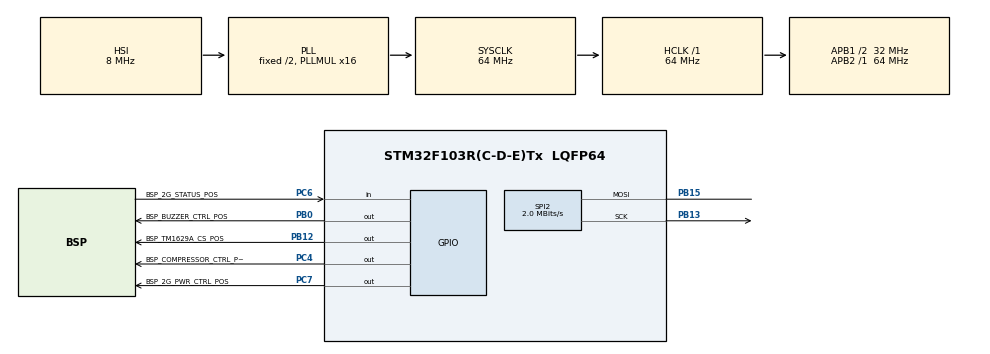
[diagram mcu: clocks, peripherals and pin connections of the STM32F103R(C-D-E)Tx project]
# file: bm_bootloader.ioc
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IWDG.Reload=4000
Mcu.Family=STM32F1
Mcu.Name=STM32F103R(C-D-E)Tx
Mcu.Package=LQFP64
NVIC.PriorityGroup=NVIC_PRIORITYGROUP_4
NVIC.SPI2_IRQn=true\:0\:0\:false\:false\:true\:true
PA13.Mode=JTAG_5_pins
PA13.Signal=SYS_JTMS-SWDIO
PA14.Mode=JTAG_5_pins
PA14.Signal=SYS_JTCK-SWCLK
PA15.Mode=JTAG_5_pins
PA15.Signal=SYS_JTDI
PB0.GPIO_Label=BSP_BUZZER_CTRL_POS
PB0.Signal=GPIO_Output
PB12.GPIO_Label=BSP_TM1629A_CS_POS
PB12.Signal=GPIO_Output
PB13.Mode=Simplex_Bidirectional_Master
PB13.Signal=SPI2_SCK
PB15.Mode=Simplex_Bidirectional_Master
PB15.Signal=SPI2_MOSI
PB3.Mode=JTAG_5_pins
PB3.Signal=SYS_JTDO-TRACESWO
PB4.Mode=JTAG_5_pins
PB4.Signal=SYS_NJTRST
PC4.GPIO_Label=BSP_COMPRESSOR_CTRL_POS
PC4.Signal=GPIO_Output
PC6.GPIO_Label=BSP_2G_STATUS_POS
PC6.GPIO_PuPd=GPIO_PULLDOWN
PC6.Signal=GPIO_Input
PC7.GPIO_Label=BSP_2G_PWR_CTRL_POS
PC7.Signal=GPIO_Output
ProjectManager.HeapSize=0x00
ProjectManager.StackSize=0x400
ProjectManager.TargetToolchain=EWARM V8
RCC.AHBFreq_Value=64000000
RCC.APB1CLKDivider=RCC_HCLK_DIV2
RCC.APB1Freq_Value=32000000
RCC.APB1TimFreq_Value=64000000
RCC.APB2Freq_Value=64000000
RCC.APB2TimFreq_Value=64000000
RCC.HCLKFreq_Value=64000000
RCC.PLLMUL=RCC_PLL_MUL16
RCC.SYSCLKFreq_VALUE=64000000
RCC.SYSCLKSource=RCC_SYSCLKSOURCE_PLLCLK
RCC.USBFreq_Value=64000000
SPI2.BaudRatePrescaler=SPI_BAUDRATEPRESCALER_16
SPI2.CalculateBaudRate=2.0 MBits/s
SPI2.Direction=SPI_DIRECTION_1LINE
SPI2.FirstBit=SPI_FIRSTBIT_LSB
SPI2.Mode=SPI_MODE_MASTER
SPI2.VirtualType=VM_MASTER
VP_IWDG_VS_IWDG.Mode=IWDG_Activate
board=custom

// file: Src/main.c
/**
  ******************************************************************************
  * @file           : main.c
  * @brief          : Main program body
  ******************************************************************************
  ** This notice applies to any and all portions of this file
  * that are not between comment pairs USER CODE BEGIN and
  * USER CODE END. Other portions of this file, whether
  * inserted by the user or by software development tools
  * are owned by their respective copyright owners.
  *
  * COPYRIGHT(c) 2019 STMicroelectronics
  *
  * Redistribution and use in source and binary forms, with or without modification,
  * are permitted provided that the following conditions are met:
  *   1. Redistributions of source code must retain the above copyright notice,
  *      this list of conditions and the following disclaimer.
  *   2. Redistributions in binary form must reproduce the above copyright notice,
  *      this list of conditions and the following disclaimer in the documentation
  *      and/or other materials provided with the distribution.
  *   3. Neither the name of STMicroelectronics nor the names of its contributors
  *      may be used to endorse or promote products derived from this software
  *      without specific prior written permission.
  *
  * THIS SOFTWARE IS PROVIDED BY THE COPYRIGHT HOLDERS AND CONTRIBUTORS "AS IS"
  * AND ANY EXPRESS OR IMPLIED WARRANTIES, INCLUDING, BUT NOT LIMITED TO, THE
  * IMPLIED WARRANTIES OF MERCHANTABILITY AND FITNESS FOR A PARTICULAR PURPOSE ARE
  * DISCLAIMED. IN NO EVENT SHALL THE COPYRIGHT HOLDER OR CONTRIBUTORS BE LIABLE
  * FOR ANY DIRECT, INDIRECT, INCIDENTAL, SPECIAL, EXEMPLARY, OR CONSEQUENTIAL
  * DAMAGES (INCLUDING, BUT NOT LIMITED TO, PROCUREMENT OF SUBSTITUTE GOODS OR
  * SERVICES; LOSS OF USE, DATA, OR PROFITS; OR BUSINESS INTERRUPTION) HOWEVER
  * CAUSED AND ON ANY THEORY OF LIABILITY, WHETHER IN CONTRACT, STRICT LIABILITY,
  * OR TORT (INCLUDING NEGLIGENCE OR OTHERWISE) ARISING IN ANY WAY OUT OF THE USE
  * OF THIS SOFTWARE, EVEN IF ADVISED OF THE POSSIBILITY OF SUCH DAMAGE.
  *
  ******************************************************************************
  */
#include "main.h"
#include "stm32f1xx_hal.h"
#include "iwdg.h"
#include "spi.h"
#include "gpio.h"

/* USER CODE BEGIN Includes */
#include "log.h"
#include "bootloader.h"
/* USER CODE END Includes */

/* USER CODE BEGIN PV */
/* Private variables ---------------------------------------------------------*/

/* USER CODE END PV */

void SystemClock_Config(void);

/* USER CODE BEGIN PFP */
/* Private function prototypes -----------------------------------------------*/

/* USER CODE END PFP */

int main(void)
{

  /* MCU Configuration----------------------------------------------------------*/

  /* Reset of all peripherals, Initializes the Flash interface and the Systick. */
  HAL_Init();

  /* Configure the system clock */
  SystemClock_Config();

  /* Initialize all configured peripherals */
  MX_GPIO_Init();
  MX_SPI2_Init();
  //MX_IWDG_Init();
  /* USER CODE BEGIN 2 */
  log_init();
  /* USER CODE END 2 */

  /* Infinite loop */
  while (1)
  {

  /* USER CODE BEGIN 3 */
  bootloader();
  }
  /* USER CODE END 3 */

}

void SystemClock_Config(void)
{

  RCC_OscInitTypeDef RCC_OscInitStruct;
  RCC_ClkInitTypeDef RCC_ClkInitStruct;

    /**Initializes the CPU, AHB and APB busses clocks
    */
  RCC_OscInitStruct.OscillatorType = RCC_OSCILLATORTYPE_HSI|RCC_OSCILLATORTYPE_LSI;
  RCC_OscInitStruct.HSIState = RCC_HSI_ON;
  RCC_OscInitStruct.HSICalibrationValue = 16;
  RCC_OscInitStruct.LSIState = RCC_LSI_ON;
  RCC_OscInitStruct.PLL.PLLState = RCC_PLL_ON;
  RCC_OscInitStruct.PLL.PLLSource = RCC_PLLSOURCE_HSI_DIV2;
  RCC_OscInitStruct.PLL.PLLMUL = RCC_PLL_MUL16;
  if (HAL_RCC_OscConfig(&RCC_OscInitStruct) != HAL_OK)
  {
    _Error_Handler(__FILE__, __LINE__);
  }

    /**Initializes the CPU, AHB and APB busses clocks
    */
  RCC_ClkInitStruct.ClockType = RCC_CLOCKTYPE_HCLK|RCC_CLOCKTYPE_SYSCLK
                              |RCC_CLOCKTYPE_PCLK1|RCC_CLOCKTYPE_PCLK2;
  RCC_ClkInitStruct.SYSCLKSource = RCC_SYSCLKSOURCE_PLLCLK;
  RCC_ClkInitStruct.AHBCLKDivider = RCC_SYSCLK_DIV1;
  RCC_ClkInitStruct.APB1CLKDivider = RCC_HCLK_DIV2;
  RCC_ClkInitStruct.APB2CLKDivider = RCC_HCLK_DIV1;

  if (HAL_RCC_ClockConfig(&RCC_ClkInitStruct, FLASH_LATENCY_2) != HAL_OK)
  {
    _Error_Handler(__FILE__, __LINE__);
  }

    /**Configure the Systick interrupt time
    */
  HAL_SYSTICK_Config(HAL_RCC_GetHCLKFreq()/1000);

    /**Configure the Systick
    */
  HAL_SYSTICK_CLKSourceConfig(SYSTICK_CLKSOURCE_HCLK);

  /* SysTick_IRQn interrupt configuration */
  HAL_NVIC_SetPriority(SysTick_IRQn, 0, 0);
}

/* USER CODE BEGIN 4 */
uint32_t log_time()
{
return HAL_GetTick();
}
/* USER CODE END 4 */

void _Error_Handler(char *file, int line)
{
  while(1)
  {
  }
}

/************************ (C) COPYRIGHT STMicroelectronics *****END OF FILE****/
